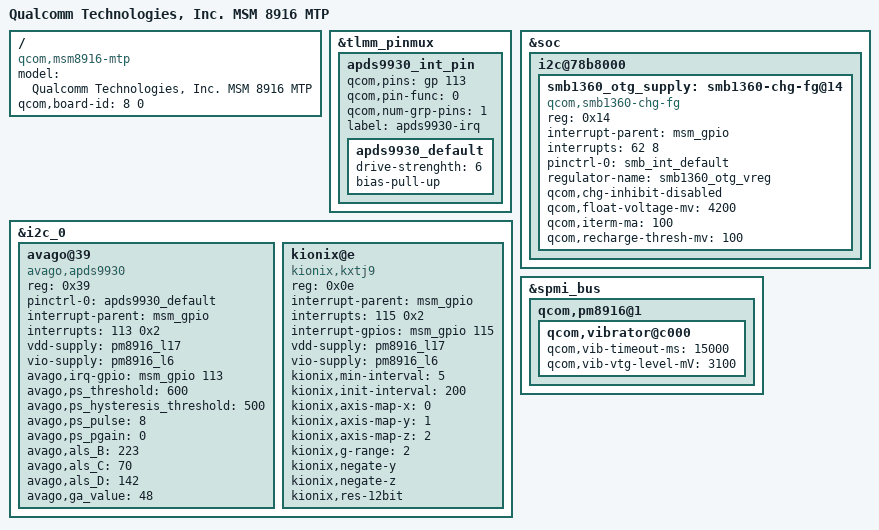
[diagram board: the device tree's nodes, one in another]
/* Copyright (c) 2014, The Linux Foundation. All rights reserved.
*
* This program is free software; you can redistribute it and/or modify
* it under the terms of the GNU General Public License version 2 and
* only version 2 as published by the Free Software Foundation.
*
* This program is distributed in the hope that it will be useful,
* but WITHOUT ANY WARRANTY; without even the implied warranty of
* MERCHANTABILITY or FITNESS FOR A PARTICULAR PURPOSE.  See the
* GNU General Public License for more details.
*/

/dts-v1/;

#include "msm8916-mtp.dtsi"

/ {
	model = "Qualcomm Technologies, Inc. MSM 8916 MTP";
	compatible = "qcom,msm8916-mtp", "qcom,msm8916", "qcom,mtp";
	qcom,board-id = <8 0>;
};

&tlmm_pinmux {
	apds9930_int_pin {
		qcom,pins = <&gp 113>;
		qcom,pin-func = <0>;
		qcom,num-grp-pins = <1>;
		label = "apds9930-irq";
		apds9930_default: apds9930_default {
			drive-strenghth = <6>;
			bias-pull-up;
		};
	};
};

&i2c_0 { /* BLSP1 QUP2 */
	avago@39 {
		compatible = "avago,apds9930";
		reg = <0x39>;
		pinctrl-names = "default";
		pinctrl-0 = <&apds9930_default>;
		interrupt-parent = <&msm_gpio>;
		interrupts = <113 0x2>;
		vdd-supply = <&pm8916_l17>;
		vio-supply = <&pm8916_l6>;
		avago,irq-gpio = <&msm_gpio 113 0x2>;
		avago,ps_threshold = <600>;
		avago,ps_hysteresis_threshold = <500>;
		avago,ps_pulse = <8>;
		avago,ps_pgain = <0>;
		avago,als_B = <223>;
		avago,als_C = <70>;
		avago,als_D = <142>;
		avago,ga_value = <48>;
	};
/*  [FEATURE]-Add-BEGIN by TCTSZ fangyou.wang, 2014/4/15,CR-65173 gsensor driver add */
	kionix@e {
		compatible = "kionix,kxtj9";
		reg = <0x0e>;
		interrupt-parent = <&msm_gpio>;
		interrupts = <115 0x2>;
		interrupt-gpios = <&msm_gpio 115 0x00>;
		vdd-supply = <&pm8916_l17>;
		vio-supply = <&pm8916_l6>;
		kionix,min-interval = <5>;
		kionix,init-interval = <200>;
		kionix,axis-map-x = <0>;
		kionix,axis-map-y = <1>;
		kionix,axis-map-z = <2>;
		kionix,g-range = <2>;
/*		kionix,negate-x;*/
		kionix,negate-y;
		kionix,negate-z;
		kionix,res-12bit;
	};

/*  [FEATURE]-Add-END by TCTSZ fangyou.wang */
};

/*[PLATFORM]-MOD BGEIN by TCTNB.YJ, 2014/04/05, modify temporarily for Alto45 power on SW*/
&soc {
	i2c@78b8000 {
		smb1360_otg_supply: smb1360-chg-fg@14 {
			compatible = "qcom,smb1360-chg-fg";
			reg = <0x14>;
			interrupt-parent = <&msm_gpio>;
			interrupts = <62 8>;
/*[BUGFIX] MOD begin by TCTSZ-fangyou.wang 2014-05-08 PR-670637*/
			pinctrl-names = "default";
			pinctrl-0 = <&smb_int_default>;
/*[BUGFIX] MOD end by TCTSZ-fangyou.wang 2014-05-08*/
			regulator-name = "smb1360_otg_vreg";

			qcom,chg-inhibit-disabled;
			qcom,float-voltage-mv = <4200>;
			qcom,iterm-ma = <100>;
			qcom,recharge-thresh-mv = <100>;
		};
	};
};
/*[PLATFORM]-END by TCTNB.YJ*/

&spmi_bus {
	qcom,pm8916@1 {
		qcom,vibrator@c000 {
			status = "okay";
			qcom,vib-timeout-ms = <15000>;
			qcom,vib-vtg-level-mV = <3100>;
		};
	};
};
